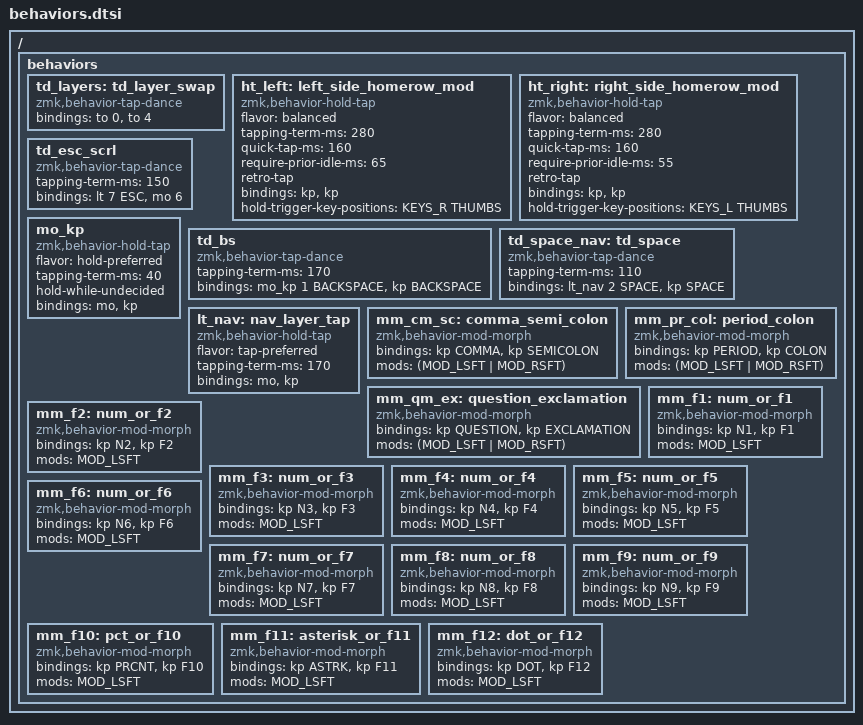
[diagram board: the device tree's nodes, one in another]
#define KEYS_L 0 1 2 3 8 9 10 11 12 13 20 21 22 23 24 25 32 33 36 37 38
#define KEYS_R 4 5 6 7 14 15 16 17 18 19 26 27 28 29 30 31 34 35 39 40
#define THUMBS 36 37 38 39 40
/ {
  behaviors {

        td_layers: td_layer_swap {
                compatible = "zmk,behavior-tap-dance";
                #binding-cells = <0>;
                bindings = <&to 0>, <&to 4>; // tap, double tap
        };

        ht_left: left_side_homerow_mod {
            compatible = "zmk,behavior-hold-tap";
            #binding-cells = <2>;
            flavor = "balanced";
            tapping-term-ms = <280>;
            quick-tap-ms = <160>;
            require-prior-idle-ms = <65>;
            retro-tap;
            bindings = <&kp>, <&kp>;
            hold-trigger-key-positions = <KEYS_R THUMBS>;
        };
        ht_right: right_side_homerow_mod {
            compatible = "zmk,behavior-hold-tap";
            #binding-cells = <2>;
            flavor = "balanced";
            tapping-term-ms = <280>;
            quick-tap-ms = <160>;
            require-prior-idle-ms = <55>;
            retro-tap;
            bindings = <&kp>, <&kp>;
            hold-trigger-key-positions = <KEYS_L THUMBS>;
        };
        td_esc_scrl: td_esc_scrl {
            compatible = "zmk,behavior-tap-dance";
            #binding-cells = <0>;
            tapping-term-ms = <150>;
            bindings = <&lt 7 ESC>, <&mo 6>; // hold, tap, double_tap
        };
        mo_kp: mo_kp {
            compatible = "zmk,behavior-hold-tap";
            #binding-cells = <2>;
            flavor       = "hold-preferred";
            tapping-term-ms = <40>;
            hold-while-undecided;
            bindings = <&mo>, <&kp>;
        };
        td_bs: td_bs {
            compatible = "zmk,behavior-tap-dance";
            #binding-cells = <0>;
            tapping-term-ms = <170>;
            bindings = <&mo_kp 1 BACKSPACE>, <&kp BACKSPACE>; // hold, tap, double_tap
        };
        td_space_nav: td_space {
            compatible = "zmk,behavior-tap-dance";
            #binding-cells = <0>;
            tapping-term-ms = <110>;
            bindings = <&lt_nav 2 SPACE>, <&kp SPACE>; // hold, tap, double_tap
        };
        lt_nav: nav_layer_tap {
            compatible = "zmk,behavior-hold-tap";
            #binding-cells = <2>;
            flavor = "tap-preferred";
            tapping-term-ms = <170>;
            bindings = <&mo>, <&kp>;
        };
        mm_cm_sc: comma_semi_colon {
            compatible    = "zmk,behavior-mod-morph";
            #binding-cells = <0>;
            bindings      = <&kp COMMA>, <&kp SEMICOLON>;
            mods          = <(MOD_LSFT | MOD_RSFT)>;
        };
        mm_pr_col: period_colon {
            compatible    = "zmk,behavior-mod-morph";
            #binding-cells = <0>;
            bindings      = <&kp PERIOD>, <&kp COLON>;
            mods          = <(MOD_LSFT | MOD_RSFT)>;
        };
        mm_qm_ex: question_exclamation {
            compatible    = "zmk,behavior-mod-morph";
            #binding-cells = <0>;
            bindings      = <&kp QUESTION>, <&kp EXCLAMATION>;
            mods          = <(MOD_LSFT | MOD_RSFT)>;
        };
        mm_f1: num_or_f1 {
            compatible    = "zmk,behavior-mod-morph";
            #binding-cells = <0>;
            bindings      = <&kp N1>, <&kp F1>;
            mods          = <MOD_LSFT>;
        };

        mm_f2: num_or_f2 {
            compatible    = "zmk,behavior-mod-morph";
            #binding-cells = <0>;
            bindings      = <&kp N2>, <&kp F2>;
            mods          = <MOD_LSFT>;
        };

        mm_f3: num_or_f3 {
            compatible    = "zmk,behavior-mod-morph";
            #binding-cells = <0>;
            bindings      = <&kp N3>, <&kp F3>;
            mods          = <MOD_LSFT>;
        };

        mm_f4: num_or_f4 {
            compatible    = "zmk,behavior-mod-morph";
            #binding-cells = <0>;
            bindings      = <&kp N4>, <&kp F4>;
            mods          = <MOD_LSFT>;
        };

        mm_f5: num_or_f5 {
            compatible    = "zmk,behavior-mod-morph";
            #binding-cells = <0>;
            bindings      = <&kp N5>, <&kp F5>;
            mods          = <MOD_LSFT>;
        };

        mm_f6: num_or_f6 {
            compatible    = "zmk,behavior-mod-morph";
            #binding-cells = <0>;
            bindings      = <&kp N6>, <&kp F6>;
            mods          = <MOD_LSFT>;
        };

        mm_f7: num_or_f7 {
            compatible    = "zmk,behavior-mod-morph";
            #binding-cells = <0>;
            bindings      = <&kp N7>, <&kp F7>;
            mods          = <MOD_LSFT>;
        };

        mm_f8: num_or_f8 {
            compatible    = "zmk,behavior-mod-morph";
            #binding-cells = <0>;
            bindings      = <&kp N8>, <&kp F8>;
            mods          = <MOD_LSFT>;
        };

        mm_f9: num_or_f9 {
            compatible    = "zmk,behavior-mod-morph";
            #binding-cells = <0>;
            bindings      = <&kp N9>, <&kp F9>;
            mods          = <MOD_LSFT>;
        };

        mm_f10: pct_or_f10 {
            compatible    = "zmk,behavior-mod-morph";
            #binding-cells = <0>;
            bindings      = <&kp PRCNT>, <&kp F10>;
            mods          = <MOD_LSFT>;
        };

        mm_f11: asterisk_or_f11 {
            compatible    = "zmk,behavior-mod-morph";
            #binding-cells = <0>;
            bindings      = <&kp ASTRK>, <&kp F11>;
            mods          = <MOD_LSFT>;
        };

        mm_f12: dot_or_f12 {
            compatible    = "zmk,behavior-mod-morph";
            #binding-cells = <0>;
            bindings      = <&kp DOT>, <&kp F12>;
            mods          = <MOD_LSFT>;
        };
  };
};
